VERSION "1"

NS_ :

BS_:

BU_: Dash DataLogger Ethanol

BO_ 256 Dash_Engine: 4 Dash
 SG_ Rpm : 0|16@1+ (1,0) [0|8000] "rpm" DataLogger
 SG_ Speed : 16|16@1+ (0.01,0) [0|655.35] "km/h" DataLogger

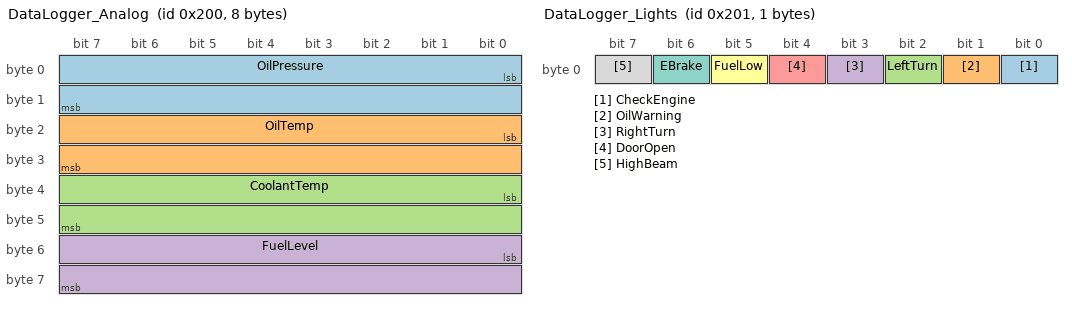
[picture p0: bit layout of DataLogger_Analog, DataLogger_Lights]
BO_ 512 DataLogger_Analog: 8 DataLogger
 SG_ OilPressure : 0|16@1+ (0.01,0) [0|655.35] "bar" Dash
 SG_ OilTemp : 16|16@1- (0.1,0) [-3276.8|3276.7] "degC" Dash
 SG_ CoolantTemp : 32|16@1- (0.1,0) [-3276.8|3276.7] "degC" Dash
 SG_ FuelLevel : 48|16@1+ (0.1,0) [0|6553.5] "%" Dash

BO_ 513 DataLogger_Lights: 1 DataLogger
 SG_ CheckEngine : 0|1@1+ (1,0) [0|1] "" Dash
 SG_ OilWarning : 1|1@1+ (1,0) [0|1] "" Dash
 SG_ LeftTurn : 2|1@1+ (1,0) [0|1] "" Dash
 SG_ RightTurn : 3|1@1+ (1,0) [0|1] "" Dash
 SG_ DoorOpen : 4|1@1+ (1,0) [0|1] "" Dash
 SG_ FuelLow : 5|1@1+ (1,0) [0|1] "" Dash
 SG_ EBrake : 6|1@1+ (1,0) [0|1] "" Dash
 SG_ HighBeam : 7|1@1+ (1,0) [0|1] "" Dash

BO_ 768 Ethanol_Data: 3 Ethanol
 SG_ EthanolContent : 0|8@1+ (1,0) [0|100] "%" Dash,DataLogger
 SG_ FuelTemp : 8|16@1- (0.1,0) [-3276.8|3276.7] "degC" Dash,DataLogger

BO_ 1793 Heartbeat_Dash: 2 Dash
 SG_ Status : 0|8@1+ (1,0) [0|255] "" DataLogger,Ethanol
 SG_ Counter : 8|8@1+ (1,0) [0|255] "" DataLogger,Ethanol

BO_ 1794 Heartbeat_DataLogger: 2 DataLogger
 SG_ Status : 0|8@1+ (1,0) [0|255] "" Dash,Ethanol
 SG_ Counter : 8|8@1+ (1,0) [0|255] "" Dash,Ethanol

BO_ 1795 Heartbeat_Ethanol: 2 Ethanol
 SG_ Status : 0|8@1+ (1,0) [0|255] "" Dash,DataLogger
 SG_ Counter : 8|8@1+ (1,0) [0|255] "" Dash,DataLogger

BA_DEF_ BO_ "GenMsgCycleTime" INT 0 65535;
BA_DEF_DEF_ "GenMsgCycleTime" 0;
BA_ "GenMsgCycleTime" BO_ 256 20;
BA_ "GenMsgCycleTime" BO_ 512 50;
BA_ "GenMsgCycleTime" BO_ 513 100;
BA_ "GenMsgCycleTime" BO_ 768 100;
BA_ "GenMsgCycleTime" BO_ 1793 1000;
BA_ "GenMsgCycleTime" BO_ 1794 1000;
BA_ "GenMsgCycleTime" BO_ 1795 1000;
